# STM32G563xx register map
File version: 1.0
Registers are 32-bit, read-write, reset 0x0 unless marked. A register's access mark holds for its fields unless they carry their own. Offsets are from the block's base; [hi:lo] are bit positions; lines under a group give offsets from that group; 'fields as' and 'values as' point back to an identical list.

## FLASH — Embedded flash memory (FLASH)
Base 0x40022000
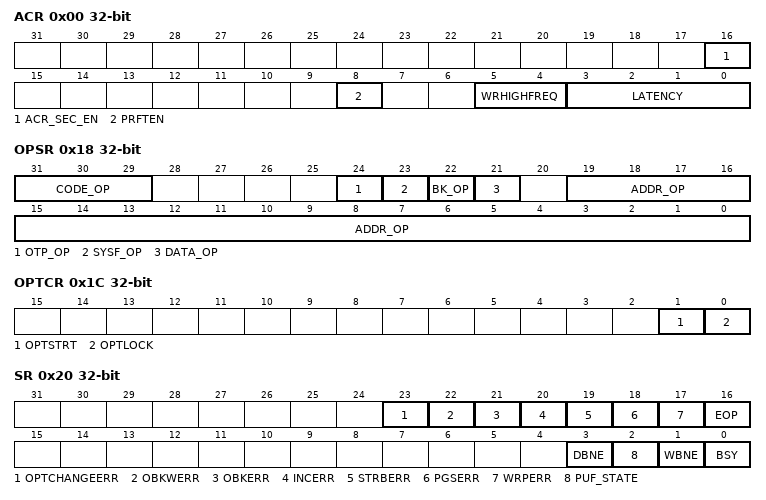
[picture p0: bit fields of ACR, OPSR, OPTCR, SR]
0x00 ACR — FLASH access control register
  [16] ACR_SEC_EN
  [8] PRFTEN
  [5:4] WRHIGHFREQ — Flash signal delay
  [3:0] LATENCY — Read latency
0x04 KEYR — FLASH nonsecure key register
  [31:0] KEY
0x08 SKEYR — FLASH secure key register
  [31:0] KEY
0x0C OPTKEYR — FLASH option key register
  [31:0] KEY
0x10 OBKKEYR — FLASH nonsecure OBK key register
  [31:0] KEY
0x14 SOBKKEYR — FLASH secure OBK key register
  [31:0] KEY
0x18 OPSR ro — FLASH operation status register
  [31:29] CODE_OP, [24] OTP_OP, [23] SYSF_OP, [22] BK_OP, [21] DATA_OP, [19:0] ADDR_OP
0x1C OPTCR — FLASH option control register
  [1] OPTSTRT, [0] OPTLOCK
0x20 SR ro — FLASH nonsecure status register
  [23] OPTCHANGEERR
  [22] OBKWERR
  [21] OBKERR
  [20] INCERR
  [19] STRBERR — strobe error flag
  [18] PGSERR
  [17] WRPERR
  [16] EOP
  [3] DBNE
  [2] PUF_STATE — PUF readiness
  [1] WBNE
  [0] BSY — busy flag
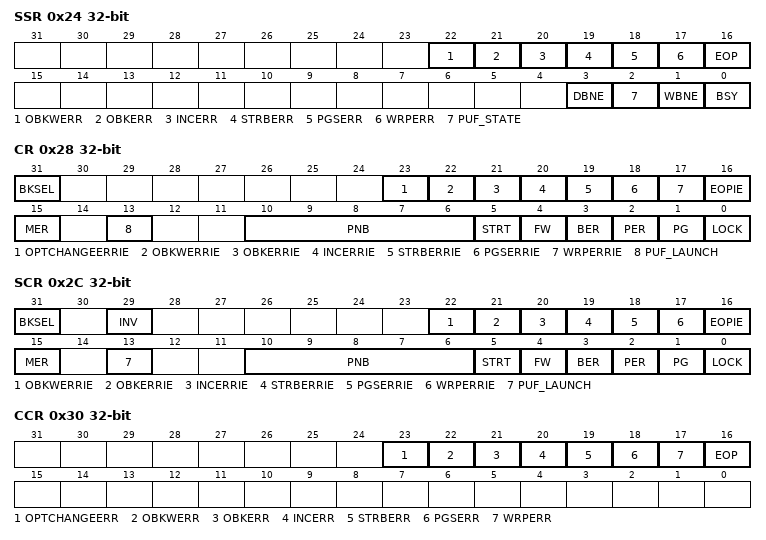
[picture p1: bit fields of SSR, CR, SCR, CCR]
0x24 SSR ro — FLASH secure status register
  [22] OBKWERR
  [21] OBKERR
  [20] INCERR
  [19] STRBERR — strobe error flag
  [18] PGSERR
  [17] WRPERR
  [16] EOP
  [3] DBNE
  [2] PUF_STATE — PUF readiness
  [1] WBNE
  [0] BSY — busy flag
0x28 CR — FLASH nonsecure control register
  [31] BKSEL — Bank selector bit
  [23] OPTCHANGEERRIE
  [22] OBKWERRIE
  [21] OBKERRIE
  [20] INCERRIE
  [19] STRBERRIE
  [18] PGSERRIE
  [17] WRPERRIE
  [16] EOPIE
  [15] MER — Mass erase request
  [13] PUF_LAUNCH
  [10:6] PNB
  [5] STRT
  [4] FW
  [3] BER — erase request
  [2] PER — page erase request
  [1] PG
  [0] LOCK
0x2C SCR — FLASH secure control register
  [31] BKSEL — bank selector bit
  [29] INV
  [22] OBKWERRIE
  [21] OBKERRIE
  [20] INCERRIE
  [19] STRBERRIE
  [18] PGSERRIE
  [17] WRPERRIE
  [16] EOPIE
  [15] MER — mass erase request
  [13] PUF_LAUNCH
  [10:6] PNB
  [5] STRT
  [4] FW
  [3] BER — erase request
  [2] PER — page erase request
  [1] PG
  [0] LOCK
0x30 CCR — FLASH nonsecure clear control register
  [23] OPTCHANGEERR
  [22] OBKWERR
  [21] OBKERR
  [20] INCERR
  [19] STRBERR
  [18] PGSERR
  [17] WRPERR
  [16] EOP — EOP flag clear bit
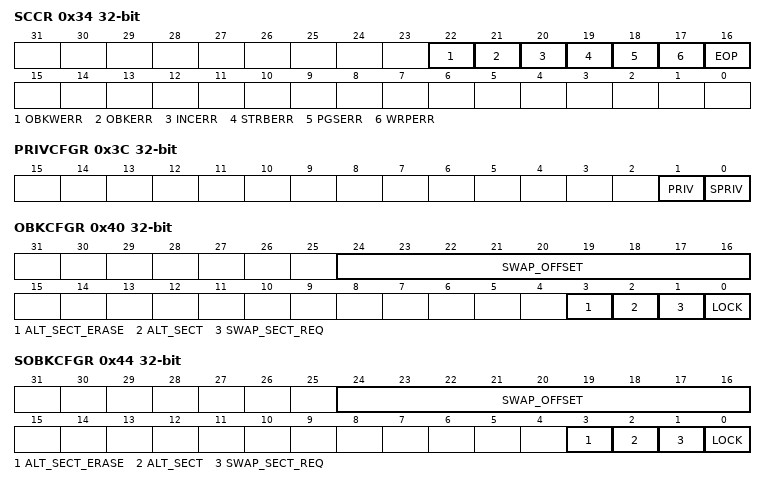
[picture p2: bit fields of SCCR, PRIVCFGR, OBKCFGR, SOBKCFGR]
0x34 SCCR — FLASH secure clear control register
  [22] OBKWERR
  [21] OBKERR
  [20] INCERR
  [19] STRBERR
  [18] PGSERR
  [17] WRPERR
  [16] EOP — EOP flag clear bit
0x3C PRIVCFGR — FLASH privilege configuration register
  [1] PRIV, [0] SPRIV
0x40 OBKCFGR — FLASH nonsecure OBK configuration register
  [24:16] SWAP_OFFSET
  [3] ALT_SECT_ERASE
  [2] ALT_SECT — alternate page bit
  [1] SWAP_SECT_REQ
  [0] LOCK
0x44 SOBKCFGR — FLASH secure OBK configuration register
  fields as OBKCFGR
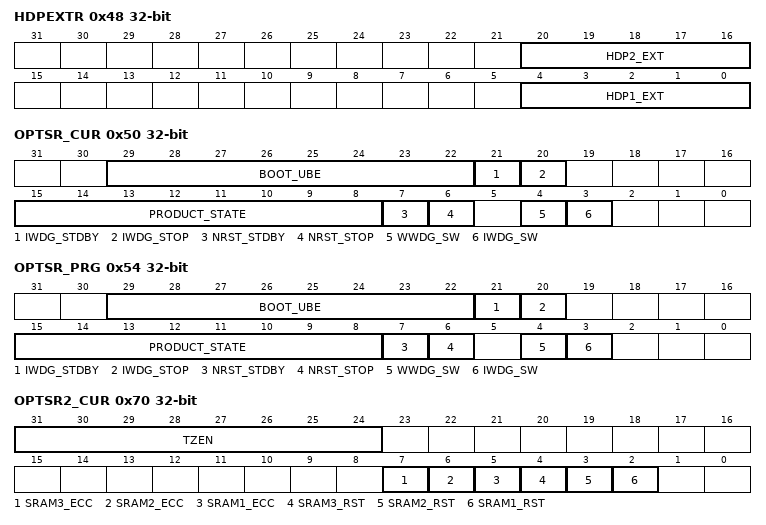
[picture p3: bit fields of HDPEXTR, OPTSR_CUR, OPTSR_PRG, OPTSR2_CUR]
0x48 HDPEXTR — FLASH HDP extension register
  [20:16] HDP2_EXT, [4:0] HDP1_EXT
0x50 OPTSR_CUR ro — FLASH option status register
  [29:22] BOOT_UBE, [21] IWDG_STDBY, [20] IWDG_STOP, [15:8] PRODUCT_STATE, [7] NRST_STDBY, [6] NRST_STOP, [4] WWDG_SW, [3] IWDG_SW
0x54 OPTSR_PRG — FLASH option status register
  fields as OPTSR_CUR
0x60 EPOCHR_CUR ro — FLASH nonsecure EPOCH register
  [23:0] EPOCH
0x64 EPOCHR_PRG — FLASH nonsecure EPOCH register
  [23:0] EPOCH
0x68 SEPOCHR_CUR ro — FLASH secure EPOCH register
  [23:0] EPOCH
0x6C SEPOCHR_PRG — FLASH secure EPOCH register
  [23:0] EPOCH
0x70 OPTSR2_CUR ro — FLASH option status register 2
  [31:24] TZEN, [7] SRAM3_ECC, [6] SRAM2_ECC, [5] SRAM1_ECC, [4] SRAM3_RST, [3] SRAM2_RST, [2] SRAM1_RST
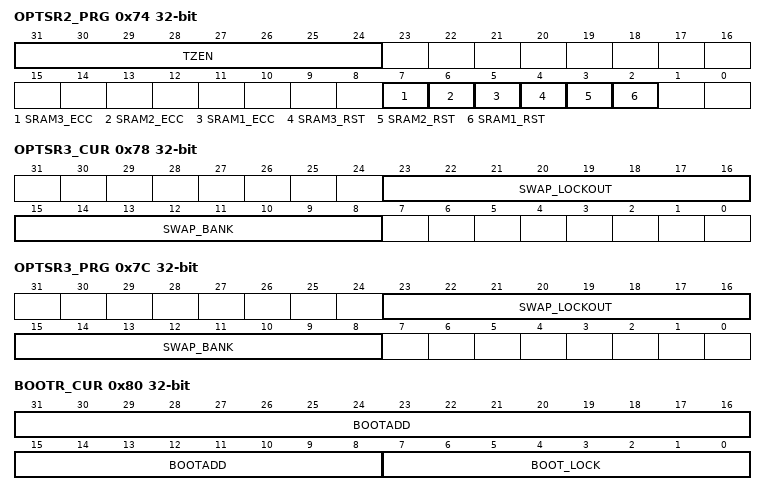
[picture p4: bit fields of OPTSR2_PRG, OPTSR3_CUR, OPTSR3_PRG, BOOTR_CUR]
0x74 OPTSR2_PRG — FLASH option status register 2
  fields as OPTSR2_CUR
0x78 OPTSR3_CUR ro — FLASH option status register 3
  [23:16] SWAP_LOCKOUT, [15:8] SWAP_BANK
0x7C OPTSR3_PRG — FLASH option status register 3
  [23:16] SWAP_LOCKOUT, [15:8] SWAP_BANK
0x80 BOOTR_CUR ro — FLASH nonsecure boot register
  [31:8] BOOTADD, [7:0] BOOT_LOCK
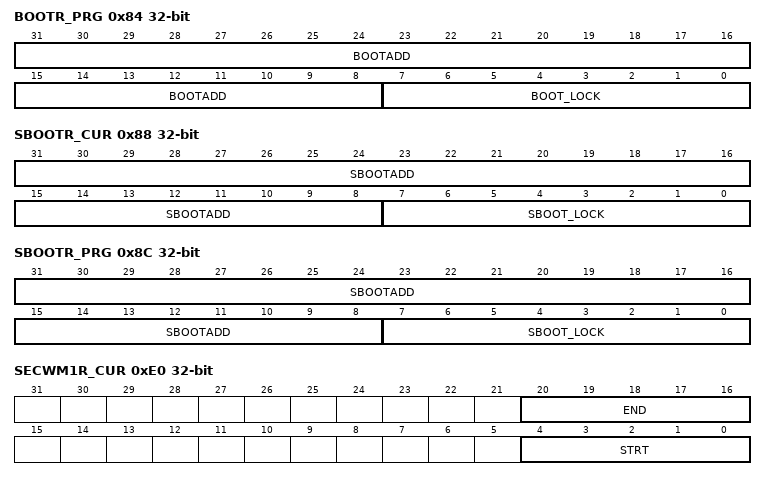
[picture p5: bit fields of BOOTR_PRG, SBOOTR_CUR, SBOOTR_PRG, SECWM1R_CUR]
0x84 BOOTR_PRG — FLASH nonsecure boot register
  [31:8] BOOTADD, [7:0] BOOT_LOCK
0x88 SBOOTR_CUR ro — FLASH secure boot register
  [31:8] SBOOTADD, [7:0] SBOOT_LOCK
0x8C SBOOTR_PRG — FLASH secure boot register
  [31:8] SBOOTADD, [7:0] SBOOT_LOCK
0x90 OTPBLR_CUR ro — FLASH nonsecure OTP block lock
  [31:0] LOCKBL — OTP block lock
0x94 OTPBLR_PRG — FLASH nonsecure OTP block lock
  [31:0] LOCKBL — OTP block lock
0x98 BL_COM_CFG_CUR ro — FLASH bootloader interface selection
  [31:0] BL_COM_CFG
0x9C BL_COM_CFG_PRG — FLASH bootloader interface selection
  [31:0] BL_COM_CFG
0xA0 SECBB1R — FLASH secure block based registers for Bank1
  [31:0] SEC1
0xC0 PRIVBB1R — FLASH privilege block based registers for Bank1
  [31:0] PRIV1
0xE0 SECWM1R_CUR ro — FLASH security watermark for Bank1
  [20:16] END, [4:0] STRT
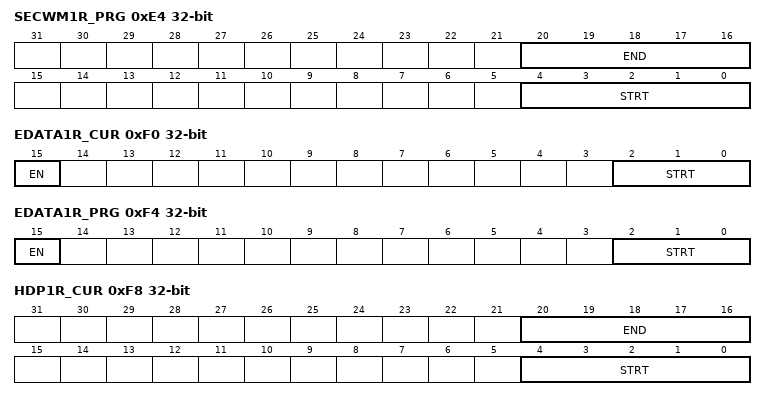
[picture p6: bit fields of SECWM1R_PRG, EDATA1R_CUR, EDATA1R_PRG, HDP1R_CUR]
0xE4 SECWM1R_PRG — FLASH security watermark for Bank1
  [20:16] END, [4:0] STRT
0xE8 WRP1R_CUR ro — FLASH write page group protection for Bank1
  [7:0] WRPG1
0xEC WRP1R_PRG — FLASH write page group protection for Bank1
  [7:0] WRPG1
0xF0 EDATA1R_CUR ro — FLASH data page configuration Bank1
  [15] EN, [2:0] STRT
0xF4 EDATA1R_PRG — FLASH data page configuration Bank1
  [15] EN, [2:0] STRT
0xF8 HDP1R_CUR ro — FLASH HDP Bank1 configuration
  [20:16] END, [4:0] STRT
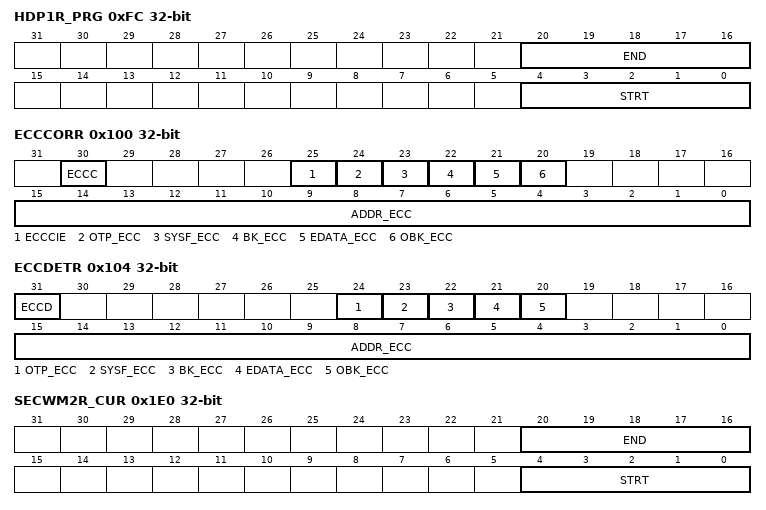
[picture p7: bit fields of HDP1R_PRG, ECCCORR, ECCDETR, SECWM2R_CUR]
0xFC HDP1R_PRG — FLASH HDP Bank1 configuration
  [20:16] END, [4:0] STRT
0x100 ECCCORR — FLASH ECC correction register
  [30] ECCC
  [25] ECCCIE
  [24] OTP_ECC — OTP ECC error bit
  [23] SYSF_ECC
  [22] BK_ECC
  [21] EDATA_ECC
  [20] OBK_ECC
  [15:0] ADDR_ECC — ECC error address
0x104 ECCDETR — FLASH ECC detection register
  [31] ECCD — ECC detection
  [24] OTP_ECC — OTP ECC error bit
  [23] SYSF_ECC
  [22] BK_ECC
  [21] EDATA_ECC
  [20] OBK_ECC
  [15:0] ADDR_ECC — ECC error address
0x108 ECCDR ro — FLASH ECC data
  [15:0] DATA_ECC — ECC error data
0x1A0 SECBB2R — FLASH secure block-based registers for Bank2
  [31:0] SEC2
0x1C0 PRIVBB2R — FLASH privilege block-based registers for Bank2
  [31:0] PRIV2
0x1E0 SECWM2R_CUR ro — FLASH security watermark for Bank2
  [20:16] END, [4:0] STRT
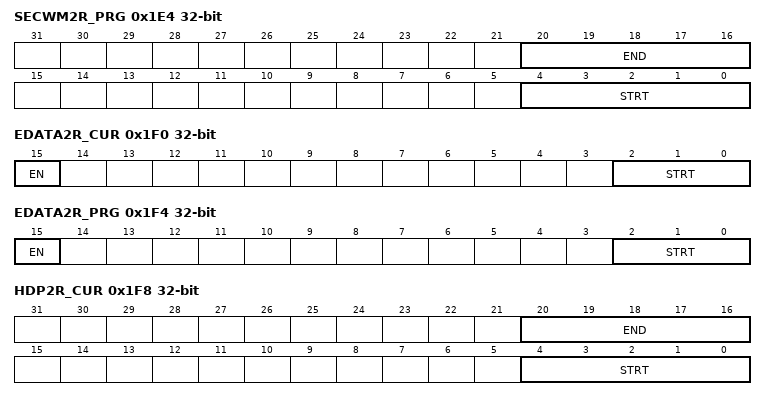
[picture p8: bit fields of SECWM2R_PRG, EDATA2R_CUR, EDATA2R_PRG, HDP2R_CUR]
0x1E4 SECWM2R_PRG — FLASH security watermark for Bank2
  [20:16] END, [4:0] STRT
0x1E8 WRP2R_CUR ro — FLASH write page group protection for Bank2
  [7:0] WRPG2
0x1EC WRP2R_PRG — FLASH write page group protection for Bank2
  [7:0] WRPG2
0x1F0 EDATA2R_CUR ro — FLASH data page configuration Bank2
  [15] EN, [2:0] STRT
0x1F4 EDATA2R_PRG — FLASH data page configuration Bank2
  [15] EN, [2:0] STRT
0x1F8 HDP2R_CUR ro — FLASH HDP Bank2 configuration
  [20:16] END, [4:0] STRT
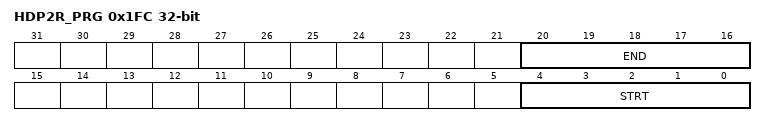
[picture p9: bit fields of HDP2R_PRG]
0x1FC HDP2R_PRG — FLASH HDP Bank2 configuration
  [20:16] END, [4:0] STRT
